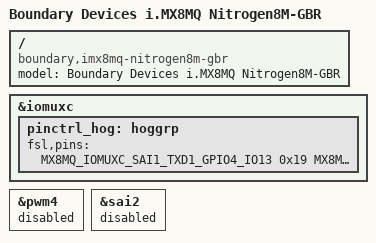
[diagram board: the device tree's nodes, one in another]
// SPDX-License-Identifier: (GPL-2.0+ OR MIT)
/*
 * Copyright 2021 Boundary Devices
 */

#include "imx8mq-nitrogen8m.dts"

/ {
	model = "Boundary Devices i.MX8MQ Nitrogen8M-GBR";
	compatible = "boundary,imx8mq-nitrogen8m-gbr", "fsl,imx8mq";
};

&iomuxc {
	/delete-node/ hoggrp;

	pinctrl_hog: hoggrp {
		fsl,pins = <
			/* #1 Control 109, Feedback 71 & 72 */
			MX8MQ_IOMUXC_SAI1_TXD1_GPIO4_IO13		0x19
			MX8MQ_IOMUXC_NAND_DATA01_GPIO3_IO7		0xd9
			MX8MQ_IOMUXC_NAND_DATA02_GPIO3_IO8		0xd9
			/* #2 Control 110, Feedback 65 & 70 */
			MX8MQ_IOMUXC_SAI1_TXD2_GPIO4_IO14		0x19
			MX8MQ_IOMUXC_NAND_CE0_B_GPIO3_IO1		0xd9
			MX8MQ_IOMUXC_NAND_DATA00_GPIO3_IO6		0xd9
			/* #3 Control 111, Feedback 64 & 73 */
			MX8MQ_IOMUXC_SAI1_TXD3_GPIO4_IO15		0x19
			MX8MQ_IOMUXC_NAND_ALE_GPIO3_IO0			0xd9
			MX8MQ_IOMUXC_NAND_DATA03_GPIO3_IO9		0xd9
			/* #4 Control 112, Feedback 74 & 125 */
			MX8MQ_IOMUXC_SAI1_TXD4_GPIO4_IO16		0x19
			MX8MQ_IOMUXC_NAND_DATA04_GPIO3_IO10		0xd9
			MX8MQ_IOMUXC_SAI3_RXC_GPIO4_IO29		0xd9
			/* #5 Control 113, Feedback 15 & 130 */
			MX8MQ_IOMUXC_SAI1_TXD5_GPIO4_IO17		0x19
			MX8MQ_IOMUXC_GPIO1_IO15_GPIO1_IO15		0xd9
			MX8MQ_IOMUXC_SAI3_MCLK_GPIO5_IO2		0xd9
			/* #6 Control 114, Feedback 5 & 124 */
			MX8MQ_IOMUXC_SAI1_TXD6_GPIO4_IO18		0x19
			MX8MQ_IOMUXC_GPIO1_IO05_GPIO1_IO5		0xd9
			MX8MQ_IOMUXC_SAI3_RXFS_GPIO4_IO28		0xd9
			/* #7 Control 115, Feedback 3 & 10 */
			MX8MQ_IOMUXC_SAI1_TXD7_GPIO4_IO19		0x19
			MX8MQ_IOMUXC_GPIO1_IO03_GPIO1_IO3		0xd9
			MX8MQ_IOMUXC_GPIO1_IO10_GPIO1_IO10		0xd9

			/* Spare GPIOs */
			MX8MQ_IOMUXC_NAND_CE3_B_GPIO3_IO4		0x19
			MX8MQ_IOMUXC_NAND_DATA05_GPIO3_IO11		0x19
			MX8MQ_IOMUXC_NAND_READY_B_GPIO3_IO16		0x19
			MX8MQ_IOMUXC_NAND_WP_B_GPIO3_IO18		0x19
			MX8MQ_IOMUXC_NAND_DQS_GPIO3_IO14		0x19
			MX8MQ_IOMUXC_SAI5_RXD2_GPIO3_IO23		0x19
			MX8MQ_IOMUXC_SAI5_RXD0_GPIO3_IO21		0x19
			MX8MQ_IOMUXC_SD2_CD_B_GPIO2_IO12		0x19
			MX8MQ_IOMUXC_SAI5_RXD1_GPIO3_IO22		0x19
			MX8MQ_IOMUXC_SAI5_MCLK_GPIO3_IO25		0x19
			MX8MQ_IOMUXC_SAI1_RXFS_GPIO4_IO0		0x19
			MX8MQ_IOMUXC_SAI1_RXC_GPIO4_IO1			0x19
			MX8MQ_IOMUXC_SAI1_RXD1_GPIO4_IO3		0x19
			MX8MQ_IOMUXC_SAI1_RXD2_GPIO4_IO4		0x19
			MX8MQ_IOMUXC_SAI1_RXD3_GPIO4_IO5		0x19
			MX8MQ_IOMUXC_SAI1_RXD4_GPIO4_IO6		0x19
			MX8MQ_IOMUXC_SAI1_RXD5_GPIO4_IO7		0x19
			MX8MQ_IOMUXC_SAI1_RXD6_GPIO4_IO8		0x19
			MX8MQ_IOMUXC_SAI1_RXD7_GPIO4_IO9		0x19
			MX8MQ_IOMUXC_SAI2_MCLK_GPIO4_IO27		0x19
			MX8MQ_IOMUXC_SAI2_RXC_GPIO4_IO22		0x19
			MX8MQ_IOMUXC_SAI2_RXD0_GPIO4_IO23		0x19
			MX8MQ_IOMUXC_SAI2_RXFS_GPIO4_IO21		0x19
			MX8MQ_IOMUXC_SAI2_TXC_GPIO4_IO25		0x19
			MX8MQ_IOMUXC_SAI2_TXD0_GPIO4_IO26		0x19
			MX8MQ_IOMUXC_SAI2_TXFS_GPIO4_IO24		0x19
		>;
	};
};

&pwm4 {
	status = "disabled";
};

&sai2 {
	status = "disabled";
};
